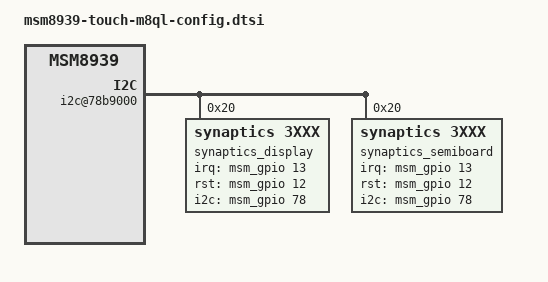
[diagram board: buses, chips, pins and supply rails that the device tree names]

/* Copyright (c) 2013, The Linux Foundation. All rights reserved.
 *
 * This program is free software; you can redistribute it and/or modify
 * it under the terms of the GNU General Public License version 2 and
 * only version 2 as published by the Free Software Foundation.
 *
 * This program is distributed in the hope that it will be useful,
 * but WITHOUT ANY WARRANTY; without even the implied warranty of
 * MERCHANTABILITY or FITNESS FOR A PARTICULAR PURPOSE.  See the
 * GNU General Public License for more details.
 */

&soc {
	i2c@78b9000 {
		synaptics_display@20 {
			compatible		= "synaptics,3xxx";
			reg			= <0x20>;
			interrupt-parent	= <&msm_gpio>;
			interrupts		= <13 0x2>;
			synaptics,display-coords= <0 1080 0 1920>;
			synaptics,irq-gpio	= <&msm_gpio 13 0x00>;
			synaptics,rst-gpio	= <&msm_gpio 12 0x00>;
			synaptics,i2c-gpio	= <&msm_gpio 78 0x00>;
			synaptics,i2c_err_hlr	= <1>;
			tw_pin_mask		= <0x05>;
			report_type		= <1>;

			config_3508_0key_metmm_4 {
				default_cfg = <1>;
				pr_number = <1790091>;
				sensor_id = <0x0>;
				syn,pl-coords = <0 1620 0 2880>;
				//cover_setting = <0x0F 0x08>;
				cover_setting = <0x12 0x08 0x08 0x0A 0x0F>;
				config = [
					4D 4C 00 03 00 3F 03 1E
					05 20 0E 54 06 40 0B 6D
					41 F0 41 00 00 00 00 0F
					1B 01 1E 05 B1 04 0E 01
					2D 16 02 0C 03 E5 C2 DD
					C5 25 0D 05 8C 00 11 12
					80 0F 0A 78 00 01 01 07
					04 04 1E 40 19 C8 26 26
					80 80 00 00 C8 C0 53 5B
					80 23 17 01 40 20 26 50
					00 00 00 00 4C 04 6C 07
					3C 32 00 00 00 00 4C 04
					6C 07 1E 05 1E 04 0A 04
					0A 00 0A 04 04 01 01 00
					01 05 0A 00 10 00 32 00
					96 00 00 00 14 03 0C 0F
					0A 00 4B 00 FF FF FF FF
					FF FF FF FF FF FF FF FF
					FF FF FF FF FF FF FF FF
					FF FF FF FF FF FF FF FF
					FF FF FF FF FF 00 04 01
					80 0D 1B 00 00 FF F4 01
					FF FF BF 64 C8 00 00 C0
					80 00 10 0A 18 00 79 01
					FA 00 00 58 02 50 00 03
					03 07 07 03 C8 00 01 04
					04 3F 00 19 00 00 00 02
					00 01 29 85 3E 00 18 00
					01 00 02 00 01 2A 04 3C
					00 17 00 02 00 02 00 01
					2B 04 3B 00 17 00 03 00
					02 00 01 2C 84 3A 00 17
					00 04 00 02 00 01 2D 84
					39 00 16 00 05 00 05 00
					02 26 04 37 00 16 00 06
					00 05 00 02 27 04 36 00
					15 00 07 00 05 00 02 28
					02 03 03 03 03 03 03 03
					03 03 03 03 03 03 03 00
					00 00 00 00 00 00 1C 00
					06 00 A6 00 14 64 00 00
					1B 02 06 FF 14 A0 00 A0
					00 50 32 1E 03 0C 0C 14
					28 04 00 00 00 00 00 00
					00 00 00 00 18 B2 07 01
					03 01 01 01 01 01 03 04
					00 03 01 0B 0B 02 02 03
					04 04 28 00 06 04 00 3F
					2D 00 05 05 00 2A 02 00
					01 00 FA 28 00 2C 01 32
					00 00 FF FF FF FF FF FF
					FF FF FF FF FF FF FF FF
					FF FF FF FF FF FF FF FF
					00 01 00 00 FF FF FF FF
					FF FF FF FF FF FF FF FF
					FF FF FF FF 28 00 2C 01
					19 00 00 00 00 FF FF FF
					FF FF FF FF FF 51 51 51
					51 CD 0D 04 83 10 10 10
					10 61 24 05 20 1F 1E 1D
					1C 1B 1A 18 17 16 15 14
					13 12 11 FF FF FF FF FF
					FF FF 00 01 02 03 04 05
					06 07 08 09 0A 0B 0C 0D
					33 32 31 30 2F 2E 2D 2C
					2B 2A 29 28 27 FF FF FF
					FF FF 00 10 00 10 00 10
					00 10 80 80 80 80 80 80
					80 80 80 80 80 80 80 80
					80 80 80 80 80 80 80 80
					80 80 80 80 80 80 80 80
					80 80 80 80 80 80 80 80
					80 80 80 80 80 80 80 80
					80 80 80 80 80 80 80 80
					00 10 00 10 00 10 00 10
					00 00 21 22 FF FF 0E 26
					FF FF
				];
			};

			config_3508_0key_metss_4 {
				default_cfg = <1>;
				pr_number = <1790091>;
				sensor_id = <0x1>;
				syn,pl-coords = <0 1620 0 2880>;
				//cover_setting = <0x0F 0x08>;
				cover_setting = <0x12 0x08 0x08 0x0A 0x0F>;
				config = [
					4D 4C 00 03 00 3F 03 1E
					05 20 0E 54 06 40 0B 6D
					41 F0 41 00 00 00 00 0F
					1B 01 1E 05 B1 04 0E 01
					2D 16 02 0C 03 E5 C2 DD
					C5 25 0D 05 8C 00 11 12
					80 0F 0A 78 00 01 01 07
					04 04 1E 40 19 C8 26 26
					80 80 00 00 C8 C0 53 5B
					80 23 17 01 40 20 26 50
					00 00 00 00 4C 04 6C 07
					3C 32 00 00 00 00 4C 04
					6C 07 1E 05 1E 04 0A 04
					0A 00 0A 04 04 01 01 00
					01 05 0A 00 10 00 32 00
					96 00 00 00 14 03 0C 0F
					0A 00 4B 00 FF FF FF FF
					FF FF FF FF FF FF FF FF
					FF FF FF FF FF FF FF FF
					FF FF FF FF FF FF FF FF
					FF FF FF FF FF 00 04 01
					80 0D 1B 00 00 FF F4 01
					FF FF BF 64 C8 00 00 C0
					80 00 10 0A 18 00 79 01
					FA 00 00 58 02 50 00 03
					03 07 07 03 C8 00 01 04
					04 3F 00 19 00 00 00 02
					00 01 29 85 3E 00 18 00
					01 00 02 00 01 2A 04 3C
					00 17 00 02 00 02 00 01
					2B 04 3B 00 17 00 03 00
					02 00 01 2C 84 3A 00 17
					00 04 00 02 00 01 2D 84
					39 00 16 00 05 00 05 00
					02 26 04 37 00 16 00 06
					00 05 00 02 27 04 36 00
					15 00 07 00 05 00 02 28
					02 03 03 03 03 03 03 03
					03 03 03 03 03 03 03 00
					00 00 00 00 00 00 1C 00
					06 00 A6 00 14 64 00 00
					1B 02 06 FF 14 A0 00 A0
					00 50 32 1E 03 0C 0C 14
					28 04 00 00 00 00 00 00
					00 00 00 00 18 B2 07 01
					03 01 01 01 01 01 03 04
					00 03 01 0B 0B 02 02 03
					04 04 28 00 06 04 00 3F
					2D 00 05 05 00 2A 02 00
					01 00 FA 28 00 2C 01 32
					00 00 FF FF FF FF FF FF
					FF FF FF FF FF FF FF FF
					FF FF FF FF FF FF FF FF
					00 01 00 00 FF FF FF FF
					FF FF FF FF FF FF FF FF
					FF FF FF FF 28 00 2C 01
					19 00 00 00 00 FF FF FF
					FF FF FF FF FF 51 51 51
					51 CD 0D 04 83 10 10 10
					10 61 24 05 20 1F 1E 1D
					1C 1B 1A 18 17 16 15 14
					13 12 11 FF FF FF FF FF
					FF FF 00 01 02 03 04 05
					06 07 08 09 0A 0B 0C 0D
					33 32 31 30 2F 2E 2D 2C
					2B 2A 29 28 27 FF FF FF
					FF FF 00 10 00 10 00 10
					00 10 80 80 80 80 80 80
					80 80 80 80 80 80 80 80
					80 80 80 80 80 80 80 80
					80 80 80 80 80 80 80 80
					80 80 80 80 80 80 80 80
					80 80 80 80 80 80 80 80
					80 80 80 80 80 80 80 80
					00 10 00 10 00 10 00 10
					00 00 21 22 FF FF 0E 26
					FF FF
				];
			};
			config_3508_0key_metmm_3 {
				default_cfg = <1>;
				pr_number = <1743766>;
				sensor_id = <0x0>;
				syn,pl-coords = <0 1620 0 2880>;
				//cover_setting = <0x0F 0x08>;
				cover_setting = <0x12 0x08 0x08 0x0A 0x0F>;
				config = [
					4D 4C 00 01 80 3F 03 1E
					05 20 0E 54 06 40 0B 6D
					41 F0 41 00 00 00 00 0F
					1B 01 1E 05 EE 0A AC 01
					2D 0B 03 0C 03 55 C5 64
					CA 25 0D 05 8C 00 13 14
					80 0F 0A 78 00 01 01 07
					04 04 1E 40 19 C8 26 26
					80 80 00 00 C8 C0 53 5B
					80 26 19 01 40 40 32 50
					00 00 00 00 4C 04 6C 07
					3C 32 00 00 00 00 4C 04
					6C 07 1E 05 1E 04 0A 04
					0A 00 0A 04 04 01 01 00
					01 05 0A 00 10 00 32 00
					96 00 00 00 14 03 0C 0F
					0A 00 4B 00 FF FF FF FF
					FF FF FF FF FF FF FF FF
					FF FF FF FF FF FF FF FF
					FF FF FF FF FF FF FF FF
					FF FF FF FF FF 00 18 01
					80 0D 1B 00 00 FF F4 01
					FF FF BF 64 C8 00 00 C0
					80 00 10 0A 18 00 79 01
					FA 00 00 58 02 50 00 06
					06 07 07 00 C8 00 01 04
					04 3E 00 18 00 00 00 02
					00 01 29 04 3D 00 17 00
					01 00 02 00 01 2B 04 3B
					00 17 00 02 00 02 00 01
					2C 04 3A 00 17 00 03 00
					02 00 01 2D 04 39 00 16
					00 04 00 05 00 02 26 04
					38 00 16 00 05 00 05 00
					02 27 04 36 00 15 00 06
					00 05 00 02 28 04 35 00
					15 00 07 00 05 00 02 28
					05 05 05 05 05 05 05 05
					05 05 05 05 05 05 05 00
					00 00 00 00 00 00 1D 00
					06 00 A6 00 14 64 00 00
					1B 02 06 FF 14 A0 00 A0
					00 50 32 1E 03 0C 0C 14
					28 04 00 00 00 00 00 00
					00 00 00 00 17 B2 07 01
					03 01 01 01 01 01 03 04
					00 03 01 0B 0B 02 02 03
					04 04 28 00 06 04 00 3E
					2D 00 05 05 00 2A 02 00
					01 00 FA 28 00 2C 01 32
					00 00 FF FF FF FF FF FF
					FF FF FF FF FF FF FF FF
					FF FF FF FF FF FF FF FF
					00 01 00 00 FF FF FF FF
					FF FF FF FF FF FF FF FF
					FF FF FF FF 28 00 2C 01
					19 00 00 00 00 FF FF FF
					FF FF FF FF FF 51 51 51
					51 CD 0D 04 83 10 10 10
					10 61 24 05 20 1F 1E 1D
					1C 1B 1A 18 17 16 15 14
					13 12 11 FF FF FF FF FF
					FF FF 00 01 02 03 04 05
					06 07 08 09 0A 0B 0C 0D
					33 32 31 30 2F 2E 2D 2C
					2B 2A 29 28 27 FF FF FF
					FF FF 00 10 00 10 00 10
					00 10 80 80 80 80 80 80
					80 80 80 80 80 80 80 80
					80 80 80 80 80 80 80 80
					80 80 80 80 80 80 80 80
					80 80 80 80 80 80 80 80
					80 80 80 80 80 80 80 80
					80 80 80 80 80 80 80 80
					00 10 00 10 00 10 00 10
					00 00 21 22 FF FF 0E 26
					FF FF
				];
			};

			config_3508_0key_metss_3 {
				default_cfg = <1>;
				pr_number = <1743766>;
				sensor_id = <0x1>;
				syn,pl-coords = <0 1620 0 2880>;
				//cover_setting = <0x0F 0x08>;
				cover_setting = <0x12 0x08 0x08 0x0A 0x0F>;
				config = [
					4D 4C 00 01 80 3F 03 1E
					05 20 0E 54 06 40 0B 6D
					41 F0 41 00 00 00 00 0F
					1B 01 1E 05 EE 0A AC 01
					2D 0B 03 0C 03 55 C5 64
					CA 25 0D 05 8C 00 13 14
					80 0F 0A 78 00 01 01 07
					04 04 1E 40 19 C8 26 26
					80 80 00 00 C8 C0 53 5B
					80 26 19 01 40 40 32 50
					00 00 00 00 4C 04 6C 07
					3C 32 00 00 00 00 4C 04
					6C 07 1E 05 1E 04 0A 04
					0A 00 0A 04 04 01 01 00
					01 05 0A 00 10 00 32 00
					96 00 00 00 14 03 0C 0F
					0A 00 4B 00 FF FF FF FF
					FF FF FF FF FF FF FF FF
					FF FF FF FF FF FF FF FF
					FF FF FF FF FF FF FF FF
					FF FF FF FF FF 00 18 01
					80 0D 1B 00 00 FF F4 01
					FF FF BF 64 C8 00 00 C0
					80 00 10 0A 18 00 79 01
					FA 00 00 58 02 50 00 06
					06 07 07 00 C8 00 01 04
					04 3E 00 18 00 00 00 02
					00 01 29 04 3D 00 17 00
					01 00 02 00 01 2B 04 3B
					00 17 00 02 00 02 00 01
					2C 04 3A 00 17 00 03 00
					02 00 01 2D 04 39 00 16
					00 04 00 05 00 02 26 04
					38 00 16 00 05 00 05 00
					02 27 04 36 00 15 00 06
					00 05 00 02 28 04 35 00
					15 00 07 00 05 00 02 28
					05 05 05 05 05 05 05 05
					05 05 05 05 05 05 05 00
					00 00 00 00 00 00 1D 00
					06 00 A6 00 14 64 00 00
					1B 02 06 FF 14 A0 00 A0
					00 50 32 1E 03 0C 0C 14
					28 04 00 00 00 00 00 00
					00 00 00 00 17 B2 07 01
					03 01 01 01 01 01 03 04
					00 03 01 0B 0B 02 02 03
					04 04 28 00 06 04 00 3E
					2D 00 05 05 00 2A 02 00
					01 00 FA 28 00 2C 01 32
					00 00 FF FF FF FF FF FF
					FF FF FF FF FF FF FF FF
					FF FF FF FF FF FF FF FF
					00 01 00 00 FF FF FF FF
					FF FF FF FF FF FF FF FF
					FF FF FF FF 28 00 2C 01
					19 00 00 00 00 FF FF FF
					FF FF FF FF FF 51 51 51
					51 CD 0D 04 83 10 10 10
					10 61 24 05 20 1F 1E 1D
					1C 1B 1A 18 17 16 15 14
					13 12 11 FF FF FF FF FF
					FF FF 00 01 02 03 04 05
					06 07 08 09 0A 0B 0C 0D
					33 32 31 30 2F 2E 2D 2C
					2B 2A 29 28 27 FF FF FF
					FF FF 00 10 00 10 00 10
					00 10 80 80 80 80 80 80
					80 80 80 80 80 80 80 80
					80 80 80 80 80 80 80 80
					80 80 80 80 80 80 80 80
					80 80 80 80 80 80 80 80
					80 80 80 80 80 80 80 80
					80 80 80 80 80 80 80 80
					00 10 00 10 00 10 00 10
					00 00 21 22 FF FF 0E 26
					FF FF
				];
			};

			config_3508_0key_metmm {
				default_cfg = <1>;
				pr_number = <1501819>;
				sensor_id = <0x0>;
				syn,pl-coords = <0 1620 0 2880>;
				//cover_setting = <0x0F 0x08>;
				//cover_setting = <0x12 0x08 0x08 0x0A 0x0F>;
				config = [
					30 30 30 30 00 3F 03 1E
					05 0E 54 06 40 0B 08 43
					87 41 00 00 00 00 0F 1B
					01 1E 05 EF 32 E0 02 28
					10 02 11 01 E7 BD DC C5
					89 80 C4 C4 05 03 12 1E
					8C 0F 0A 20 00 01 01 07
					04 04 0A C0 19 64 26 26
					80 80 00 00 57 1C 00 15
					40 32 50 00 32 00 00 00
					00 4C 04 6C 07 3C 32 00
					00 00 00 4C 04 6C 07 1E
					05 00 00 00 01 05 0A 00
					00 FF 00 06 01 80 04 1B
					00 00 00 64 00 00 00 BE
					4B 96 00 00 C0 80 00 10
					0A 18 00 79 00 02 00 00
					90 01 02 00 03 03 07 07
					03 96 00 01 04 06 56 00
					14 00 00 00 02 00 01 29
					86 54 00 13 00 01 00 02
					00 01 2A 06 52 00 13 00
					02 00 02 00 01 2B 86 50
					00 12 00 03 00 02 00 01
					2C 06 4F 00 12 00 04 00
					02 00 01 2D 86 4D 00 12
					00 05 00 05 00 02 26 86
					4B 00 11 00 06 00 05 00
					02 27 06 4A 00 11 00 07
					00 05 00 02 28 08 08 08
					08 08 08 08 08 08 08 08
					08 08 08 08 00 00 00 00
					00 00 00 1D 00 05 00 A6
					00 14 64 05 00 1B 00 11
					0A 32 0A 32 14 20 46 00
					00 00 FF FF FF FF FF FF
					FF FF 51 51 51 51 CD 0D
					04 83 10 10 10 10 05 20
					1F 1E 1D 1C 1B 1A 18 17
					16 15 14 13 12 11 FF FF
					FF FF FF FF FF 00 01 02
					03 04 05 06 07 08 09 0A
					0B 0C 0D 33 32 31 30 2F
					2E 2D 2C 2B 2A 29 28 27
					FF FF FF FF FF 00 10 00
					10 00 10 00 10 80 80 80
					80 80 80 80 80 80 80 80
					80 80 80 80 80 80 80 80
					80 80 80 80 80 80 80 80
					80 80 80 80 80 80 80 80
					80 80 80 80 80 80 80 80
					80 80 80 80 80 80 80 80
					80 80 80 00 10 00 10 00
					10 00 10
				];
			};

			config_3508_0key_metss {
				default_cfg = <1>;
				pr_number = <1501819>;
				sensor_id = <0x1>;
				syn,pl-coords = <0 1620 0 2880>;
				//cover_setting = <0x0F 0x08>;
				//cover_setting = <0x12 0x08 0x08 0x0A 0x0F>;
				config = [
					30 30 30 30 00 3F 03 1E
					05 0E 54 06 40 0B 08 43
					87 41 00 00 00 00 0F 1B
					01 1E 05 EF 32 E0 02 28
					10 02 11 01 E7 BD DC C5
					89 80 C4 C4 05 03 12 1E
					8C 0F 0A 20 00 01 01 07
					04 04 0A C0 19 64 26 26
					80 80 00 00 57 1C 00 15
					40 32 50 00 32 00 00 00
					00 4C 04 6C 07 3C 32 00
					00 00 00 4C 04 6C 07 1E
					05 00 00 00 01 05 0A 00
					00 FF 00 06 01 80 04 1B
					00 00 00 64 00 00 00 BE
					4B 96 00 00 C0 80 00 10
					0A 18 00 79 00 02 00 00
					90 01 02 00 03 03 07 07
					03 96 00 01 04 06 56 00
					14 00 00 00 02 00 01 29
					86 54 00 13 00 01 00 02
					00 01 2A 06 52 00 13 00
					02 00 02 00 01 2B 86 50
					00 12 00 03 00 02 00 01
					2C 06 4F 00 12 00 04 00
					02 00 01 2D 86 4D 00 12
					00 05 00 05 00 02 26 86
					4B 00 11 00 06 00 05 00
					02 27 06 4A 00 11 00 07
					00 05 00 02 28 08 08 08
					08 08 08 08 08 08 08 08
					08 08 08 08 00 00 00 00
					00 00 00 1D 00 05 00 A6
					00 14 64 05 00 1B 00 11
					0A 32 0A 32 14 20 46 00
					00 00 FF FF FF FF FF FF
					FF FF 51 51 51 51 CD 0D
					04 83 10 10 10 10 05 20
					1F 1E 1D 1C 1B 1A 18 17
					16 15 14 13 12 11 FF FF
					FF FF FF FF FF 00 01 02
					03 04 05 06 07 08 09 0A
					0B 0C 0D 33 32 31 30 2F
					2E 2D 2C 2B 2A 29 28 27
					FF FF FF FF FF 00 10 00
					10 00 10 00 10 80 80 80
					80 80 80 80 80 80 80 80
					80 80 80 80 80 80 80 80
					80 80 80 80 80 80 80 80
					80 80 80 80 80 80 80 80
					80 80 80 80 80 80 80 80
					80 80 80 80 80 80 80 80
					80 80 80 00 10 00 10 00
					10 00 10
				];
			};
		};

		synaptics_semiboard@20 {
			compatible		= "synaptics,3xxx";
			reg			= <0x20>;
			interrupt-parent	= <&msm_gpio>;
			interrupts		= <13 0x2>;
			synaptics,display-coords= <0 1080 0 1920>;
			synaptics,irq-gpio	= <&msm_gpio 13 0x00>;
			synaptics,rst-gpio	= <&msm_gpio 12 0x00>;
			synaptics,i2c-gpio	= <&msm_gpio 78 0x00>;
			synaptics,i2c_err_hlr	= <1>;
			tw_pin_mask		= <0x05>;
			report_type		= <1>;

			config_3508_0key_metmm_2 {
				default_cfg = <1>;
				pr_number = <1743766>;
				sensor_id = <0x0>;
				syn,pl-coords = <0 1620 0 2880>;
				//cover_setting = <0x0F 0x08>;
				config = [
					4D 4C 00 01 00 3F 03 14
					05 20 0E 54 06 40 0B 6D
					41 F0 41 00 00 00 00 0F
					1B 01 1E 05 F5 28 1E 05
					28 14 01 14 01 C7 C7 B4
					CC 25 0D 05 8C 00 05 0A
					46 0F 0A 78 00 01 01 07
					04 04 0A C0 19 C8 26 26
					80 80 00 00 50 C0 53 5B
					80 27 20 01 40 23 28 50
					00 00 00 00 4C 04 6C 07
					3C 32 00 00 00 00 4C 04
					6C 07 1E 05 1E 04 0A 04
					0A 00 0A 04 04 01 01 00
					01 05 0A 00 10 00 32 00
					96 00 00 00 14 03 0C 0F
					0A 00 4B 00 FF FF FF FF
					FF FF FF FF FF FF FF FF
					FF FF FF FF FF FF FF FF
					FF FF FF FF FF FF FF FF
					FF FF FF FF FF 00 2C 01
					80 04 1B 00 00 FF D0 07
					FF FF BF 96 D0 07 00 C0
					80 00 10 0A 18 00 79 05
					08 00 00 F4 01 01 00 03
					03 07 07 03 F4 01 01 04
					04 3F 00 17 00 00 00 02
					00 01 2B 84 3D 00 16 00
					02 00 05 00 02 26 04 39
					00 15 00 04 00 05 00 02
					28 84 36 00 14 00 08 00
					05 00 02 2A 83 33 00 13
					00 0B 00 03 00 01 25 83
					30 00 12 00 0E 00 03 00
					01 27 83 2D 00 11 00 12
					00 07 00 02 24 03 2A 00
					10 00 16 00 07 00 02 26
					08 08 08 08 08 08 08 08
					08 08 08 08 08 08 08 00
					00 00 00 00 00 00 1F 00
					06 00 A6 00 14 64 00 00
					1B 02 06 FF 28 A0 00 A0
					00 50 32 1E 03 0C 0C 14
					28 04 00 00 00 00 00 00
					00 00 00 00 16 19 07 01
					03 01 01 01 01 01 03 04
					00 03 01 0B 0B 02 02 03
					04 04 6F 04 8F 04 00 3E
					2D 00 05 05 00 2A 02 00
					00 00 FA 28 00 2C 01 32
					00 00 FF FF FF FF FF FF
					FF FF FF FF FF FF FF FF
					FF FF FF FF FF FF FF FF
					00 01 00 00 FF FF FF FF
					FF FF FF FF FF FF FF FF
					FF FF FF FF 28 00 2C 01
					19 00 00 00 00 FF FF FF
					FF FF FF FF FF 51 51 51
					51 02 0D 04 83 10 10 10
					10 61 24 05 20 1F 1E 1D
					1C 1B 1A 18 17 16 15 14
					13 12 11 FF FF FF FF FF
					FF FF 00 01 02 03 04 05
					06 07 08 09 0A 0B 0C 0D
					33 32 31 30 2F 2E 2D 2C
					2B 2A 29 28 27 FF FF FF
					FF FF 00 10 00 10 00 10
					00 10 80 80 80 80 80 80
					80 80 80 80 80 80 80 80
					80 80 80 80 80 80 80 80
					80 80 80 80 80 80 80 80
					80 80 80 80 80 80 80 80
					80 80 80 80 80 80 80 80
					80 80 80 80 80 80 80 80
					00 10 00 10 00 10 00 10
					00 00 21 22 FF FF 0E 26
					35 FF
				];
			};

			config_3508_0key_metss_2 {
				default_cfg = <1>;
				pr_number = <1743766>;
				sensor_id = <0x1>;
				syn,pl-coords = <0 1620 0 2880>;
				//cover_setting = <0x0F 0x08>;
				config = [
					4D 4C 00 01 00 3F 03 14
					05 20 0E 54 06 40 0B 6D
					41 F0 41 00 00 00 00 0F
					1B 01 1E 05 F5 28 1E 05
					28 14 01 14 01 C7 C7 B4
					CC 25 0D 05 8C 00 05 0A
					46 0F 0A 78 00 01 01 07
					04 04 0A C0 19 C8 26 26
					80 80 00 00 50 C0 53 5B
					80 27 20 01 40 23 28 50
					00 00 00 00 4C 04 6C 07
					3C 32 00 00 00 00 4C 04
					6C 07 1E 05 1E 04 0A 04
					0A 00 0A 04 04 01 01 00
					01 05 0A 00 10 00 32 00
					96 00 00 00 14 03 0C 0F
					0A 00 4B 00 FF FF FF FF
					FF FF FF FF FF FF FF FF
					FF FF FF FF FF FF FF FF
					FF FF FF FF FF FF FF FF
					FF FF FF FF FF 00 2C 01
					80 04 1B 00 00 FF D0 07
					FF FF BF 96 D0 07 00 C0
					80 00 10 0A 18 00 79 05
					08 00 00 F4 01 01 00 03
					03 07 07 03 F4 01 01 04
					04 3F 00 17 00 00 00 02
					00 01 2B 84 3D 00 16 00
					02 00 05 00 02 26 04 39
					00 15 00 04 00 05 00 02
					28 84 36 00 14 00 08 00
					05 00 02 2A 83 33 00 13
					00 0B 00 03 00 01 25 83
					30 00 12 00 0E 00 03 00
					01 27 83 2D 00 11 00 12
					00 07 00 02 24 03 2A 00
					10 00 16 00 07 00 02 26
					08 08 08 08 08 08 08 08
					08 08 08 08 08 08 08 00
					00 00 00 00 00 00 1F 00
					06 00 A6 00 14 64 00 00
					1B 02 06 FF 28 A0 00 A0
					00 50 32 1E 03 0C 0C 14
					28 04 00 00 00 00 00 00
					00 00 00 00 16 19 07 01
					03 01 01 01 01 01 03 04
					00 03 01 0B 0B 02 02 03
					04 04 6F 04 8F 04 00 3E
					2D 00 05 05 00 2A 02 00
					00 00 FA 28 00 2C 01 32
					00 00 FF FF FF FF FF FF
					FF FF FF FF FF FF FF FF
					FF FF FF FF FF FF FF FF
					00 01 00 00 FF FF FF FF
					FF FF FF FF FF FF FF FF
					FF FF FF FF 28 00 2C 01
					19 00 00 00 00 FF FF FF
					FF FF FF FF FF 51 51 51
					51 02 0D 04 83 10 10 10
					10 61 24 05 20 1F 1E 1D
					1C 1B 1A 18 17 16 15 14
					13 12 11 FF FF FF FF FF
					FF FF 00 01 02 03 04 05
					06 07 08 09 0A 0B 0C 0D
					33 32 31 30 2F 2E 2D 2C
					2B 2A 29 28 27 FF FF FF
					FF FF 00 10 00 10 00 10
					00 10 80 80 80 80 80 80
					80 80 80 80 80 80 80 80
					80 80 80 80 80 80 80 80
					80 80 80 80 80 80 80 80
					80 80 80 80 80 80 80 80
					80 80 80 80 80 80 80 80
					80 80 80 80 80 80 80 80
					00 10 00 10 00 10 00 10
					00 00 21 22 FF FF 0E 26
					35 FF
				];
			};

			config_3508_0key_metmm_1 {
				default_cfg = <1>;
				pr_number = <1661113>;
				sensor_id = <0x0>;
				syn,pl-coords = <0 1620 0 2880>;
				//cover_setting = <0x0F 0x08>;
				config = [
					4D 45 43 06 00 3F 03 14
					05 51 0E 54 06 40 0B 08
					43 87 41 00 00 00 00 0F
					1B 01 1E 05 F5 28 1E 05
					28 14 01 14 01 C7 C7 B4
					CC 25 0D 05 8C 05 0A 46
					0F 0A 78 00 01 01 07 04
					04 0A C0 19 C8 26 26 80
					80 00 00 50 C0 53 5B 80
					27 20 01 40 23 28 50 00
					00 00 00 4C 04 6C 07 3C
					32 00 00 00 00 4C 04 6C
					07 1E 05 1E 04 0A 04 0A
					00 0A 04 04 01 01 00 01
					05 0A 00 10 00 00 00 14
					03 0C 0F 0A 00 4B 00 FF
					FF FF FF FF FF FF FF FF
					FF FF FF FF FF FF FF FF
					FF FF FF FF FF FF FF FF
					FF FF FF FF FF FF FF FF
					00 2C 01 80 04 1B 00 00
					FF D0 07 FF FF BF 96 D0
					07 00 C0 80 00 10 0A 18
					00 79 05 08 00 00 F4 01
					01 00 03 03 07 07 03 F4
					01 01 04 04 3F 00 17 00
					00 00 02 00 01 2B 84 3D
					00 16 00 02 00 05 00 02
					26 04 39 00 15 00 04 00
					05 00 02 28 84 36 00 14
					00 08 00 05 00 02 2A 83
					33 00 13 00 0B 00 03 00
					01 25 83 30 00 12 00 0E
					00 03 00 01 27 83 2D 00
					11 00 12 00 07 00 02 24
					03 2A 00 10 00 16 00 07
					00 02 26 08 08 08 08 08
					08 08 08 08 08 08 08 08
					08 08 00 00 00 00 00 00
					00 1F 00 06 00 A6 00 14
					64 00 00 1B 02 06 FF 28
					A0 00 A0 00 50 32 1E 03
					0C 0C 14 28 04 00 00 00
					00 00 00 00 00 00 00 16
					19 06 00 07 05 0E 0E 03
					03 07 04 01 05 03 0F 0F
					06 06 05 04 04 28 00 05
					04 00 3F 2D 00 05 00 00
					00 00 00 00 00 00 00 FF
					FF FF FF FF FF FF FF 51
					51 51 51 CD 0D 04 83 10
					10 10 10 05 20 1F 1E 1D
					1C 1B 1A 18 17 16 15 14
					13 12 11 FF FF FF FF FF
					FF FF 00 01 02 03 04 05
					06 07 08 09 0A 0B 0C 0D
					33 32 31 30 2F 2E 2D 2C
					2B 2A 29 28 27 FF FF FF
					FF FF 00 10 00 10 00 10
					00 10 80 80 80 80 80 80
					80 80 80 80 80 80 80 80
					80 80 80 80 80 80 80 80
					80 80 80 80 80 80 80 80
					80 80 80 80 80 80 80 80
					80 80 80 80 80 80 80 80
					80 80 80 80 80 80 80 80
					00 10 00 10 00 10 00 10
					00 00 21 22 FF FF 0E 26
					35 FF 01 02 02 04
				];
			};

			config_3508_0key_metss_1 {
				default_cfg = <1>;
				pr_number = <1661113>;
				sensor_id = <0x1>;
				syn,pl-coords = <0 1620 0 2880>;
				//cover_setting = <0x0F 0x08>;
				config = [
					4D 45 43 06 00 3F 03 14
					05 51 0E 54 06 40 0B 08
					43 87 41 00 00 00 00 0F
					1B 01 1E 05 F5 28 1E 05
					28 14 01 14 01 C7 C7 B4
					CC 25 0D 05 8C 05 0A 46
					0F 0A 78 00 01 01 07 04
					04 0A C0 19 C8 26 26 80
					80 00 00 50 C0 53 5B 80
					27 20 01 40 23 28 50 00
					00 00 00 4C 04 6C 07 3C
					32 00 00 00 00 4C 04 6C
					07 1E 05 1E 04 0A 04 0A
					00 0A 04 04 01 01 00 01
					05 0A 00 10 00 00 00 14
					03 0C 0F 0A 00 4B 00 FF
					FF FF FF FF FF FF FF FF
					FF FF FF FF FF FF FF FF
					FF FF FF FF FF FF FF FF
					FF FF FF FF FF FF FF FF
					00 2C 01 80 04 1B 00 00
					FF D0 07 FF FF BF 96 D0
					07 00 C0 80 00 10 0A 18
					00 79 05 08 00 00 F4 01
					01 00 03 03 07 07 03 F4
					01 01 04 04 3F 00 17 00
					00 00 02 00 01 2B 84 3D
					00 16 00 02 00 05 00 02
					26 04 39 00 15 00 04 00
					05 00 02 28 84 36 00 14
					00 08 00 05 00 02 2A 83
					33 00 13 00 0B 00 03 00
					01 25 83 30 00 12 00 0E
					00 03 00 01 27 83 2D 00
					11 00 12 00 07 00 02 24
					03 2A 00 10 00 16 00 07
					00 02 26 08 08 08 08 08
					08 08 08 08 08 08 08 08
					08 08 00 00 00 00 00 00
					00 1F 00 06 00 A6 00 14
					64 00 00 1B 02 06 FF 28
					A0 00 A0 00 50 32 1E 03
					0C 0C 14 28 04 00 00 00
					00 00 00 00 00 00 00 16
					19 06 00 07 05 0E 0E 03
					03 07 04 01 05 03 0F 0F
					06 06 05 04 04 28 00 05
					04 00 3F 2D 00 05 00 00
					00 00 00 00 00 00 00 FF
					FF FF FF FF FF FF FF 51
					51 51 51 CD 0D 04 83 10
					10 10 10 05 20 1F 1E 1D
					1C 1B 1A 18 17 16 15 14
					13 12 11 FF FF FF FF FF
					FF FF 00 01 02 03 04 05
					06 07 08 09 0A 0B 0C 0D
					33 32 31 30 2F 2E 2D 2C
					2B 2A 29 28 27 FF FF FF
					FF FF 00 10 00 10 00 10
					00 10 80 80 80 80 80 80
					80 80 80 80 80 80 80 80
					80 80 80 80 80 80 80 80
					80 80 80 80 80 80 80 80
					80 80 80 80 80 80 80 80
					80 80 80 80 80 80 80 80
					80 80 80 80 80 80 80 80
					00 10 00 10 00 10 00 10
					00 00 21 22 FF FF 0E 26
					35 FF 01 02 02 04
				];
			};
		};
	};
};
